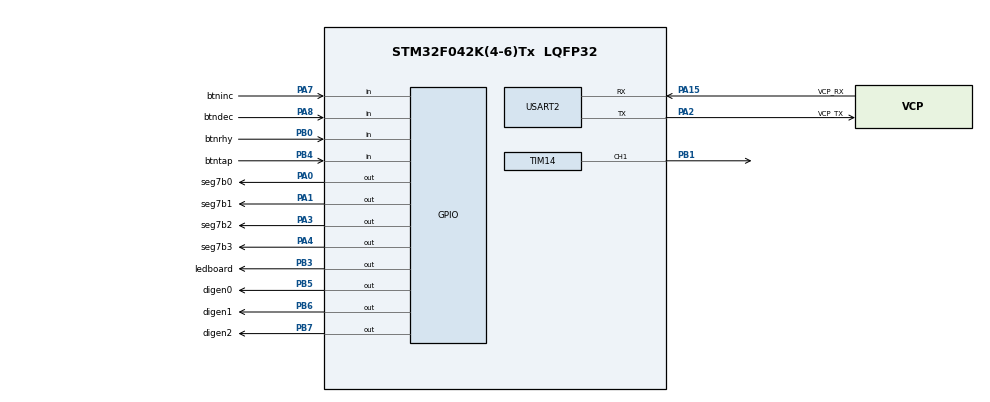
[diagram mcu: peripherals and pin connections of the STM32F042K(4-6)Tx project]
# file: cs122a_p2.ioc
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Mcu.Family=STM32F0
Mcu.Name=STM32F042K(4-6)Tx
Mcu.Package=LQFP32
NVIC.TIM16_IRQn=true\:0\:0\:false\:false\:true\:true\:true\:true
PA0.GPIO_Label=seg7b0
PA0.Signal=GPIO_Output
PA1.GPIO_Label=seg7b1
PA1.Signal=GPIO_Output
PA13.GPIO_Label=SWDIO
PA13.Mode=Serial_Wire
PA13.Signal=SYS_SWDIO
PA14.GPIO_Label=SWCLK
PA14.Mode=Serial_Wire
PA14.Signal=SYS_SWCLK
PA15.GPIO_Label=VCP_RX
PA15.Mode=Asynchronous
PA15.Signal=USART2_RX
PA2.GPIO_Label=VCP_TX
PA2.Mode=Asynchronous
PA2.Signal=USART2_TX
PA3.GPIO_Label=seg7b2
PA3.Signal=GPIO_Output
PA4.GPIO_Label=seg7b3
PA4.Signal=GPIO_Output
PA7.GPIO_Label=btninc
PA7.GPIO_PuPd=GPIO_PULLUP
PA7.Signal=GPIO_Input
PA8.GPIO_Label=btndec
PA8.GPIO_PuPd=GPIO_PULLUP
PA8.Signal=GPIO_Input
PB0.GPIO_Label=btnrhy
PB0.GPIO_PuPd=GPIO_PULLUP
PB0.Signal=GPIO_Input
PB1.Signal=S_TIM14_CH1
PB3.GPIO_Label=ledboard
PB3.Signal=GPIO_Output
PB4.GPIO_Label=btntap
PB4.GPIO_PuPd=GPIO_PULLUP
PB4.Signal=GPIO_Input
PB5.GPIO_Label=digen0
PB5.Signal=GPIO_Output
PB6.GPIO_Label=digen1
PB6.Signal=GPIO_Output
PB7.GPIO_Label=digen2
PB7.Signal=GPIO_Output
PF0-OSC_IN.GPIO_Label=MCO
PF0-OSC_IN.Mode=HSE-External-Clock-Source
PF0-OSC_IN.Signal=RCC_OSC_IN
ProjectManager.HeapSize=0x200
ProjectManager.StackSize=0x400
ProjectManager.TargetToolchain=STM32CubeIDE
SH.S_TIM14_CH1.0=TIM14_CH1,PWM Generation1 CH1
TIM14.Channel=TIM_CHANNEL_1
TIM14.Period=44-1
TIM14.Prescaler=80-1
TIM14.Pulse=22
USART2.VirtualMode-Asynchronous=VM_ASYNC
VP_TIM14_VS_ClockSourceINT.Mode=Enable_Timer
VP_TIM16_VS_ClockSourceINT.Mode=Enable_Timer
board=NUCLEO-F042K6

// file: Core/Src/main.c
/* USER CODE BEGIN Header */
/**
  ******************************************************************************
  * @file           : main.c
  * @brief          : Main program body
  ******************************************************************************
  * @attention
  *
  * Copyright (c) 2023 STMicroelectronics.
  * All rights reserved.
  *
  * This software is licensed under terms that can be found in the LICENSE file
  * in the root directory of this software component.
  * If no LICENSE file comes with this software, it is provided AS-IS.
  *
  ******************************************************************************
  */
/* USER CODE END Header */
#include "main.h"
#include "tim.h"
#include "usart.h"
#include "gpio.h"

/* USER CODE BEGIN Includes */
#include "scheduler.h"
/* USER CODE END Includes */

void SystemClock_Config(void);

int main(void)
{

  /* MCU Configuration--------------------------------------------------------*/

  /* Reset of all peripherals, Initializes the Flash interface and the Systick. */
  HAL_Init();

  /* Configure the system clock */
  SystemClock_Config();

  /* Initialize all configured peripherals */
  MX_GPIO_Init();
  MX_USART2_UART_Init();
  MX_TIM16_Init();
  MX_TIM14_Init();
  /* USER CODE BEGIN 2 */
  HAL_TIM_Base_Start_IT(&htim16);
  /* USER CODE END 2 */

  /* Infinite loop */
  while (1)
  {

  }
}

void SystemClock_Config(void)
{
  RCC_OscInitTypeDef RCC_OscInitStruct = {0};
  RCC_ClkInitTypeDef RCC_ClkInitStruct = {0};

  /** Initializes the RCC Oscillators according to the specified parameters
  * in the RCC_OscInitTypeDef structure.
  */
  RCC_OscInitStruct.OscillatorType = RCC_OSCILLATORTYPE_HSI;
  RCC_OscInitStruct.HSIState = RCC_HSI_ON;
  RCC_OscInitStruct.HSICalibrationValue = RCC_HSICALIBRATION_DEFAULT;
  RCC_OscInitStruct.PLL.PLLState = RCC_PLL_NONE;
  if (HAL_RCC_OscConfig(&RCC_OscInitStruct) != HAL_OK)
  {
    Error_Handler();
  }

  /** Initializes the CPU, AHB and APB buses clocks
  */
  RCC_ClkInitStruct.ClockType = RCC_CLOCKTYPE_HCLK|RCC_CLOCKTYPE_SYSCLK
                              |RCC_CLOCKTYPE_PCLK1;
  RCC_ClkInitStruct.SYSCLKSource = RCC_SYSCLKSOURCE_HSI;
  RCC_ClkInitStruct.AHBCLKDivider = RCC_SYSCLK_DIV1;
  RCC_ClkInitStruct.APB1CLKDivider = RCC_HCLK_DIV1;

  if (HAL_RCC_ClockConfig(&RCC_ClkInitStruct, FLASH_LATENCY_0) != HAL_OK)
  {
    Error_Handler();
  }
}

/* USER CODE BEGIN 4 */
void HAL_TIM_PeriodElapsedCallback(TIM_HandleTypeDef *htim)
{
  if (htim == &htim16)
  {
    scheduler_tick();
  }
}
/* USER CODE END 4 */

void Error_Handler(void)
{
  __disable_irq();
  while (1)
  {
  }
}
